AUTOSAR XML (schema 4-0-3)
package /ComponentTypes
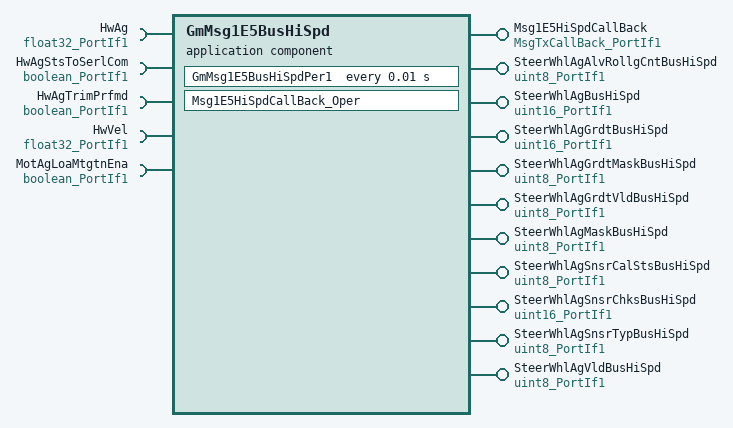
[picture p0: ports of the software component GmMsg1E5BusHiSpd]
  application sw component type GmMsg1E5BusHiSpd
    11 x provide port:
      Msg1E5HiSpdCallBack: server-com-spec{operation=Oper, queue-length=1}, provided-interface=MsgTxCallBack_PortIf1
      SteerWhlAgAlvRollgCntBusHiSpd: nonqueued-sender-com-spec{data-element=Val, init-value=0}, provided-interface=uint8_PortIf1
      SteerWhlAgBusHiSpd: nonqueued-sender-com-spec{data-element=Val, init-value=0}, provided-interface=uint16_PortIf1
      SteerWhlAgGrdtBusHiSpd: nonqueued-sender-com-spec{data-element=Val, init-value=0}, provided-interface=uint16_PortIf1
      SteerWhlAgGrdtMaskBusHiSpd: nonqueued-sender-com-spec{data-element=Val, init-value=0}, provided-interface=uint8_PortIf1
      SteerWhlAgGrdtVldBusHiSpd: nonqueued-sender-com-spec{data-element=Val, init-value=0}, provided-interface=uint8_PortIf1
      SteerWhlAgMaskBusHiSpd: nonqueued-sender-com-spec{data-element=Val, init-value=0}, provided-interface=uint8_PortIf1
      SteerWhlAgSnsrCalStsBusHiSpd: nonqueued-sender-com-spec{data-element=Val, init-value=0}, provided-interface=uint8_PortIf1
      SteerWhlAgSnsrChksBusHiSpd: nonqueued-sender-com-spec{data-element=Val, init-value=0}, provided-interface=uint16_PortIf1
      SteerWhlAgSnsrTypBusHiSpd: nonqueued-sender-com-spec{data-element=Val, init-value=0}, provided-interface=uint8_PortIf1
      SteerWhlAgVldBusHiSpd: nonqueued-sender-com-spec{data-element=Val, init-value=0}, provided-interface=uint8_PortIf1
    5 x require port:
      HwAg: nonqueued-receiver-com-spec{data-element=Val, filter=data-filter-type=ALWAYS, init-value=0}, required-interface=float32_PortIf1
      HwAgStsToSerlCom: nonqueued-receiver-com-spec{data-element=Logl, filter=data-filter-type=ALWAYS, init-value=0}, required-interface=boolean_PortIf1
      HwAgTrimPrfmd: nonqueued-receiver-com-spec{data-element=Logl, filter=data-filter-type=ALWAYS, init-value=0}, required-interface=boolean_PortIf1
      HwVel: nonqueued-receiver-com-spec{data-element=Val, filter=data-filter-type=ALWAYS, init-value=0}, required-interface=float32_PortIf1
      MotAgLoaMtgtnEna: nonqueued-receiver-com-spec{data-element=Logl, filter=data-filter-type=ALWAYS, init-value=0}, required-interface=boolean_PortIf1
    behavior GmMsg1E5BusHiSpd_InternalBehavior: data-type-mapping=Nexteer
      ar-typed-per-instance-memorys:
        data GmMsg1E5BusHiSpdRollgCntr: sw-calibration-access=READ-ONLY, type=uint8
      timing event TMT_GM0C9HSPer1: start-on-event=GmMsg1E5BusHiSpdPer1, period=0.01
      operation invoked event OIT_Msg1E5HiSpdCallBack_Oper_Msg1E5HiSpdCallBack_Oper: start-on-event=Msg1E5HiSpdCallBack_Oper, operation=Msg1E5HiSpdCallBack.Oper
      runnable GmMsg1E5BusHiSpdPer1
        data-receive-point-by-arguments:
          5 x access:
            REC_HwAg_Val: accessed-variable=HwAg.Val
            REC_HwAgCalCmpl_Logl: accessed-variable=HwAgTrimPrfmd.Logl
            REC_HwAgVld_Logl: accessed-variable=HwAgStsToSerlCom.Logl
            REC_HwVel_Val: accessed-variable=HwVel.Val
            REC_MotAgLoaMtgtnEna_Logl: accessed-variable=MotAgLoaMtgtnEna.Logl
        data-send-points:
          10 x access:
            SEND_GM1E5HSSteerWhlAg_Val: accessed-variable=SteerWhlAgBusHiSpd.Val
            SEND_GM1E5HSSteerWhlAgAlvRollgCnt_Val: accessed-variable=SteerWhlAgAlvRollgCntBusHiSpd.Val
            SEND_GM1E5HSSteerWhlAgGrdt_Val: accessed-variable=SteerWhlAgGrdtBusHiSpd.Val
            SEND_GM1E5HSSteerWhlAgGrdtMask_Val: accessed-variable=SteerWhlAgGrdtMaskBusHiSpd.Val
            SEND_GM1E5HSSteerWhlAgGrdtVld_Val: accessed-variable=SteerWhlAgGrdtVldBusHiSpd.Val
            SEND_GM1E5HSSteerWhlAgMask_Val: accessed-variable=SteerWhlAgMaskBusHiSpd.Val
            SEND_GM1E5HSSteerWhlAgSnsrCalSts_Val: accessed-variable=SteerWhlAgSnsrCalStsBusHiSpd.Val
            SEND_GM1E5HSSteerWhlAgSnsrChks_Val: accessed-variable=SteerWhlAgSnsrChksBusHiSpd.Val
            SEND_GM1E5HSSteerWhlAgSnsrTyp_Val: accessed-variable=SteerWhlAgSnsrTypBusHiSpd.Val
            SEND_GM1E5HSSteerWhlAgVld_Val: accessed-variable=SteerWhlAgVldBusHiSpd.Val
      runnable Msg1E5HiSpdCallBack_Oper
  swc implementation GmMsg1E5BusHiSpd_Implementation: behavior=GmMsg1E5BusHiSpd_InternalBehavior
    code-descriptors:
      code Default: artifact-descriptors=autosar-engineering-object={short-label=Default, category=SWSRC}
